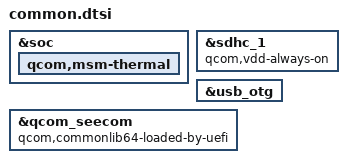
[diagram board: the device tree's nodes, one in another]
#include "pinctrl.dtsi"

#include "audio.dtsi"
#include "battery_usb.dtsi"
#include "camera.dtsi"
#include "display.dtsi"
#include "pm8937.dtsi"
#include "touchscreen.dtsi"
#include "vibrator.dtsi"

&soc {
		qcom,msm-thermal {
		};
};

&sdhc_1 {
	qcom,vdd-always-on;
};

&usb_otg {
	/delete-property/ qcom,hsusb-otg-default-mode;
};

&qcom_seecom {
	qcom,commonlib64-loaded-by-uefi;
};
